# HDSC_HC32F005 register map
Vendor: HDSC Co.Ltd; Series: ARMCM0P; File version: 1.2
CPU: CM0 r0p0, little endian, no MPU, no FPU, 3 interrupt priority bits
Registers are 32-bit, read-write, reset 0x0 unless marked. A register's access mark holds for its fields unless they carry their own. Offsets are from the block's base; [hi:lo] are bit positions; {n}, {i} and the like mark numbered series; 'fields as' and 'values as' point back to an identical list.

## I2C
Base 0x40000400
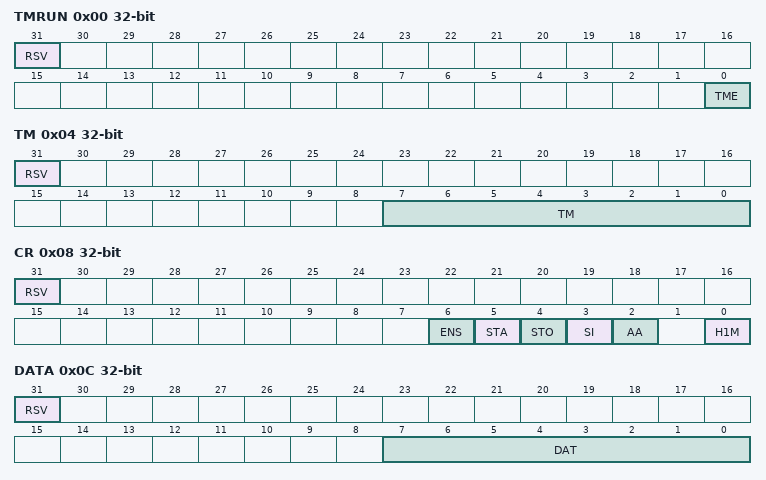
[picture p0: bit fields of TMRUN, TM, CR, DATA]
0x00 TMRUN (reset mask 0x1)
  [31] RSV, [0] TME
0x04 TM (reset mask 0xFF)
  [31] RSV, [7:0] TM
0x08 CR (reset mask 0x7D)
  [31] RSV, [6] ENS, [5] STA, [4] STO, [3] SI, [2] AA, [0] H1M
0x0C DATA (reset mask 0xFF)
  [31] RSV, [7:0] DAT
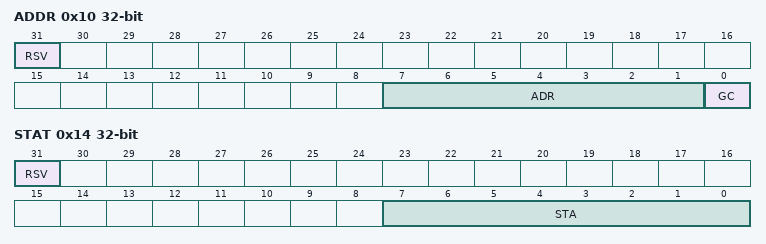
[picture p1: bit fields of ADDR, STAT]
0x10 ADDR (reset mask 0xFF)
  [31] RSV, [7:1] ADR, [0] GC
0x14 STAT ro (reset mask 0xFF)
  [31] RSV rw, [7:0] STA

## LVD
Base 0x40002400; alternate view of ADC
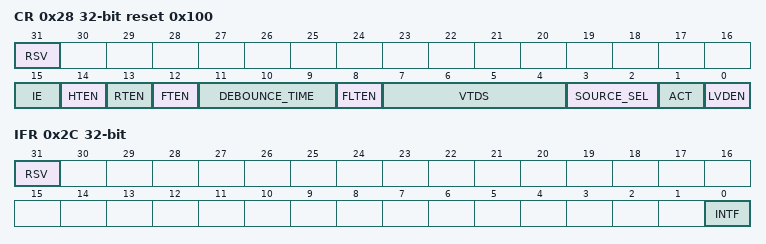
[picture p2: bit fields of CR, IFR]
0x28 CR reset 0x100 (reset mask 0xFFFF)
  [31] RSV, [15] IE, [14] HTEN, [13] RTEN, [12] FTEN, [11:9] DEBOUNCE_TIME, [8] FLTEN, [7:4] VTDS, [3:2] SOURCE_SEL, [1] ACT, [0] LVDEN
0x2C IFR (reset mask 0x1)
  [31] RSV, [0] INTF

## PCA
Base 0x40001000
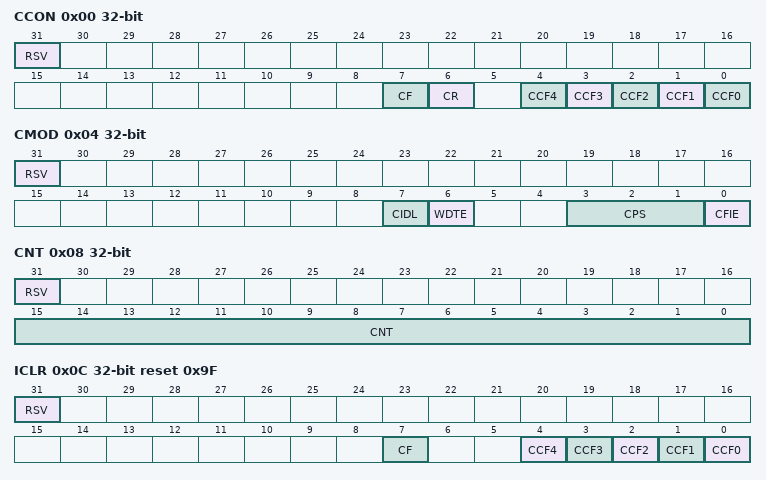
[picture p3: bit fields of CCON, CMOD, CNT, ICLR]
0x00 CCON (reset mask 0xDF)
  [31] RSV, [7] CF, [6] CR, [n] CCF{n} (n=0..4)
0x04 CMOD (reset mask 0xCF)
  [31] RSV, [7] CIDL, [6] WDTE, [3:1] CPS, [0] CFIE
0x08 CNT (reset mask 0xFFFF)
  [31] RSV, [15:0] CNT
0x0C ICLR wo reset 0x9F (reset mask 0x9F)
  [31] RSV rw, [7] CF, [n] CCF{n} (n=0..4)
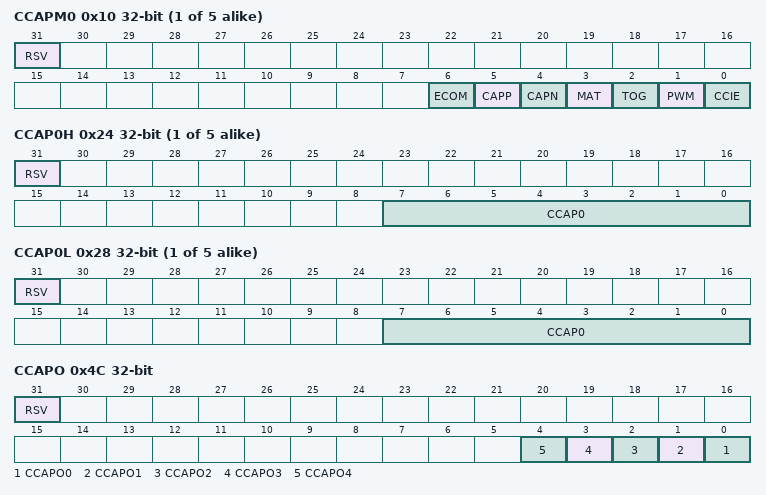
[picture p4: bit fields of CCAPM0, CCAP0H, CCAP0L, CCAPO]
{0x10+4i} CCAPM{i} (reset mask 0x7F) (i=0..4)
  [31] RSV, [6] ECOM, [5] CAPP, [4] CAPN, [3] MAT, [2] TOG, [1] PWM, [0] CCIE
{0x24+8i} CCAP{i}H (reset mask 0xFF) (i=0..4)
  [31] RSV, [7:0] CCAP{i}
{0x28+8i} CCAP{i}L (reset mask 0xFF) (i=0..4)
  [31] RSV, [7:0] CCAP{i}
0x4C CCAPO (reset mask 0x1F)
  [31] RSV, [n] CCAPO{n} (n=0..4)
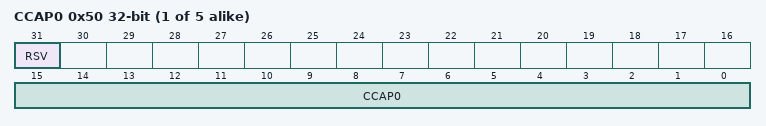
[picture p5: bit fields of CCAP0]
{0x50+4i} CCAP{i} (reset mask 0xFFFF) (i=0..4)
  [31] RSV, [15:0] CCAP{i}

## RAM
Base 0x40020400
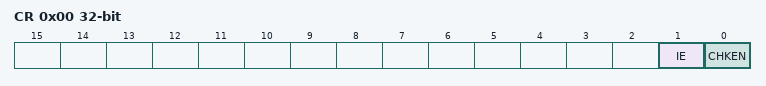
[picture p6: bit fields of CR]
0x00 CR
  [1] IE, [0] CHKEN
0x04 ERRADDR ro
  [11:0] ERRADDR
0x08 IFR ro
  [0] ERR
0x0C ICLR ro
  [0] ERRCLR wo

## RESET
Base 0x4000201C
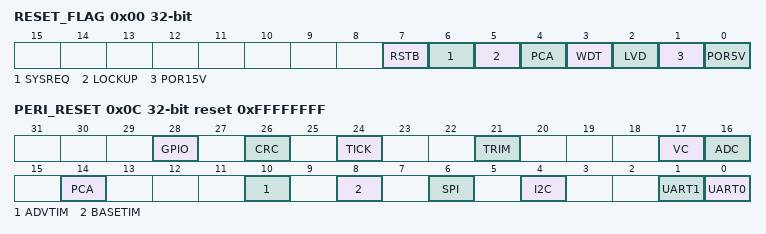
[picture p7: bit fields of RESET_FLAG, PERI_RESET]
0x00 RESET_FLAG
  [7] RSTB, [6] SYSREQ, [5] LOCKUP, [4] PCA, [3] WDT, [2] LVD, [1] POR15V, [0] POR5V
0x0C PERI_RESET reset 0xFFFFFFFF
  [28] GPIO, [26] CRC, [24] TICK, [21] TRIM, [17] VC, [16] ADC, [14] PCA, [10] ADVTIM, [8] BASETIM, [6] SPI, [4] I2C, [1] UART1, [0] UART0

## SPI
Base 0x40000800
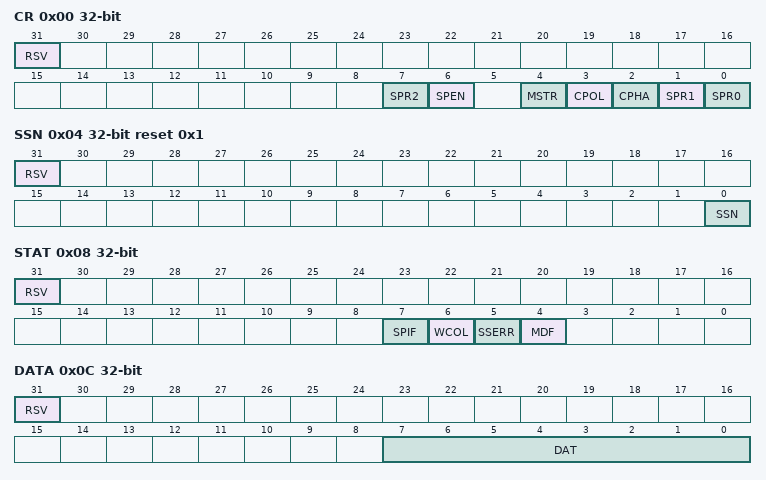
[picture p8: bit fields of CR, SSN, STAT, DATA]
0x00 CR (reset mask 0xDF)
  [31] RSV, [7] SPR2, [6] SPEN, [4] MSTR, [3] CPOL, [2] CPHA, [1] SPR1, [0] SPR0
0x04 SSN reset 0x1 (reset mask 0x1)
  [31] RSV, [0] SSN
0x08 STAT ro (reset mask 0xBE)
  [31] RSV rw, [7] SPIF, [6] WCOL, [5] SSERR, [4] MDF
0x0C DATA (reset mask 0xFF)
  [31] RSV, [7:0] DAT

## SYSCTRL
Base 0x40002000
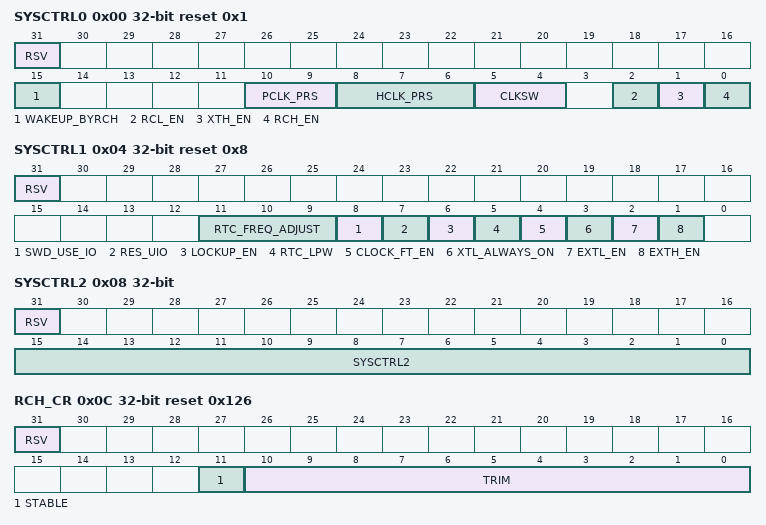
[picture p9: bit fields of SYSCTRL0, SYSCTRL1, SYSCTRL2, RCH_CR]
0x00 SYSCTRL0 reset 0x1 (reset mask 0x9FFF)
  [31] RSV, [15] WAKEUP_BYRCH, [10:9] PCLK_PRS, [8:6] HCLK_PRS, [5:4] CLKSW, [2] RCL_EN, [1] XTH_EN, [0] RCH_EN
0x04 SYSCTRL1 reset 0x8 (reset mask 0xF7E)
  [31] RSV, [11:9] RTC_FREQ_ADJUST, [8] SWD_USE_IO, [7] RES_UIO, [6] LOCKUP_EN, [5] RTC_LPW, [4] CLOCK_FT_EN, [3] XTL_ALWAYS_ON, [2] EXTL_EN, [1] EXTH_EN
0x08 SYSCTRL2 wo (reset mask 0xFFFF)
  [31] RSV rw, [15:0] SYSCTRL2
0x0C RCH_CR reset 0x126 (reset mask 0xFFF)
  [31] RSV, [11] STABLE ro, [10:0] TRIM
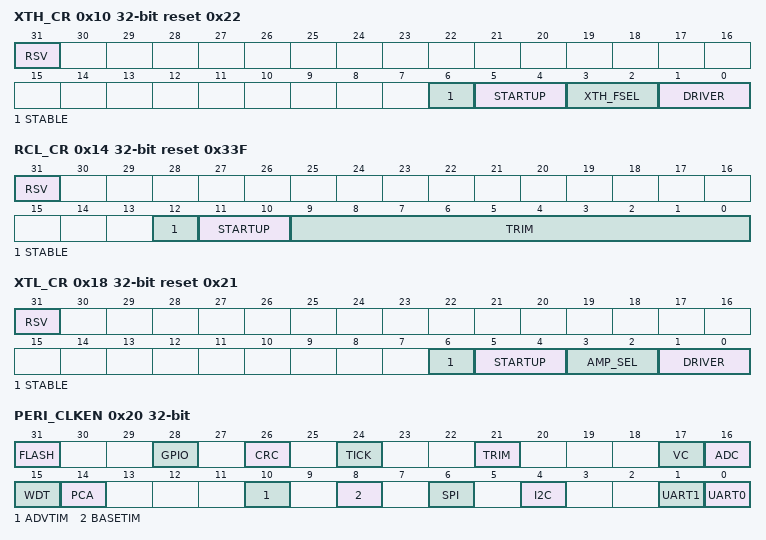
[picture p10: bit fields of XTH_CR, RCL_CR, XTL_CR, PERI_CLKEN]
0x10 XTH_CR reset 0x22 (reset mask 0x7F)
  [31] RSV, [6] STABLE ro, [5:4] STARTUP, [3:2] XTH_FSEL, [1:0] DRIVER
0x14 RCL_CR reset 0x33F (reset mask 0x1FFF)
  [31] RSV, [12] STABLE ro, [11:10] STARTUP, [9:0] TRIM
0x18 XTL_CR reset 0x21 (reset mask 0x7F)
  [31] RSV, [6] STABLE ro, [5:4] STARTUP, [3:2] AMP_SEL, [1:0] DRIVER
0x20 PERI_CLKEN
  [31] FLASH, [28] GPIO, [26] CRC, [24] TICK, [21] TRIM, [17] VC, [16] ADC, [15] WDT, [14] PCA, [10] ADVTIM, [8] BASETIM, [6] SPI, [4] I2C, [1] UART1, [0] UART0
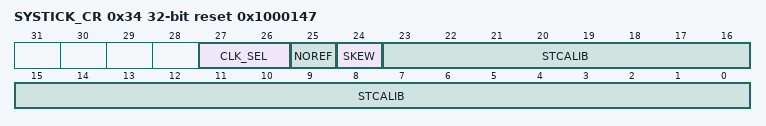
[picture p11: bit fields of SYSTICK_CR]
0x34 SYSTICK_CR reset 0x1000147
  [27:26] CLK_SEL, [25] NOREF, [24] SKEW, [23:0] STCALIB

## TIM0 — desc TIM
Base 0x40000C00
Same registers: TIM1 0x40000C20, TIM2 0x40000C40
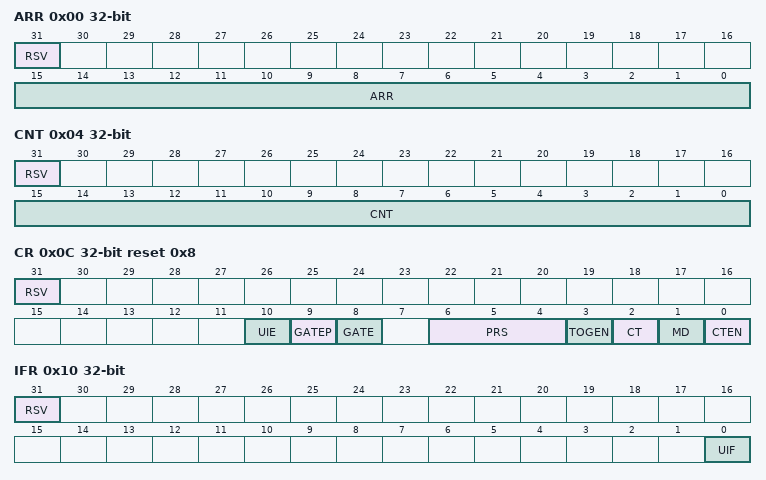
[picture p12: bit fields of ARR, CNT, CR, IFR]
0x00 ARR (reset mask 0xFFFF)
  [31] RSV, [15:0] ARR
0x04 CNT (reset mask 0xFFFF)
  [31] RSV, [15:0] CNT
0x08 CNT32
0x0C CR reset 0x8 (reset mask 0x77F)
  [31] RSV, [10] UIE, [9] GATEP, [8] GATE, [6:4] PRS, [3] TOGEN, [2] CT, [1] MD, [0] CTEN
0x10 IFR ro (reset mask 0x1)
  [31] RSV rw, [0] UIF
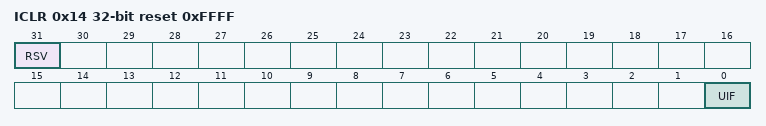
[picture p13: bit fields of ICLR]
0x14 ICLR wo reset 0xFFFF (reset mask 0x1)
  [31] RSV rw, [0] UIF

## UART0 — desc UART
Base 0x40000000
Same registers: UART1 0x40000100
0x00 SBUF
  [7:0] SBUF
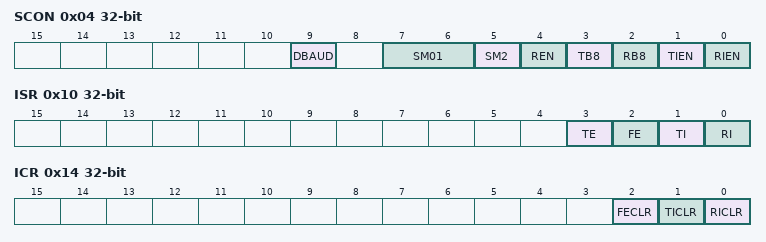
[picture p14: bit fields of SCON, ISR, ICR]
0x04 SCON
  [9] DBAUD, [7:6] SM01, [5] SM2, [4] REN, [3] TB8, [2] RB8, [1] TIEN, [0] RIEN
0x08 SADDR
  [7:0] SADDR
0x0C SADEN
  [7:0] SADEN
0x10 ISR ro
  [3] TE, [2] FE, [1] TI, [0] RI
0x14 ICR wo
  [2] FECLR, [1] TICLR rw, [0] RICLR rw

## VC
Base 0x40002400; alternate view of ADC
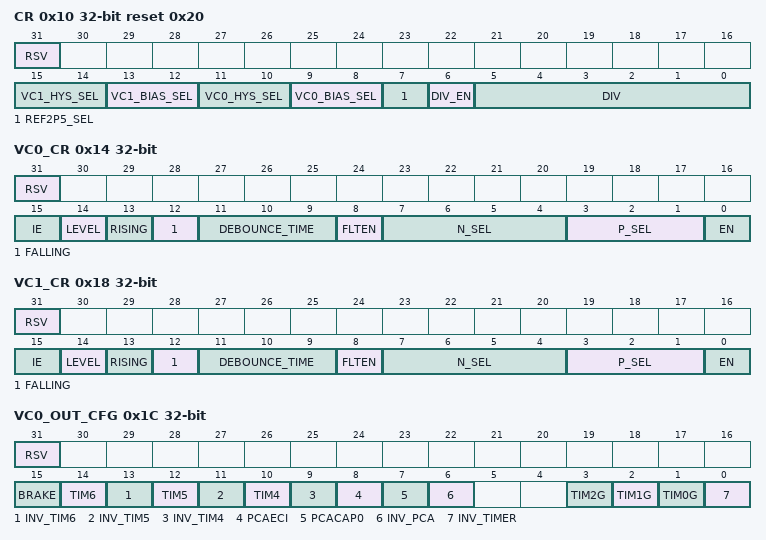
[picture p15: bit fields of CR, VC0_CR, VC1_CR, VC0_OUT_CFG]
0x10 CR reset 0x20 (reset mask 0xFFFF)
  [31] RSV, [15:14] VC1_HYS_SEL, [13:12] VC1_BIAS_SEL, [11:10] VC0_HYS_SEL, [9:8] VC0_BIAS_SEL, [7] REF2P5_SEL, [6] DIV_EN, [5:0] DIV
0x14 VC0_CR (reset mask 0x1FFFF)
  [31] RSV, [15] IE, [14] LEVEL, [13] RISING, [12] FALLING, [11:9] DEBOUNCE_TIME, [8] FLTEN, [7:4] N_SEL, [3:1] P_SEL, [0] EN
0x18 VC1_CR (reset mask 0x1FFFF)
  fields as VC0_CR
0x1C VC0_OUT_CFG (reset mask 0xFE3F)
  [31] RSV, [15] BRAKE, [14] TIM6, [13] INV_TIM6, [12] TIM5, [11] INV_TIM5, [10] TIM4, [9] INV_TIM4, [8] PCAECI, [7] PCACAP0, [6] INV_PCA, [3] TIM2G, [2] TIM1G, [1] TIM0G, [0] INV_TIMER
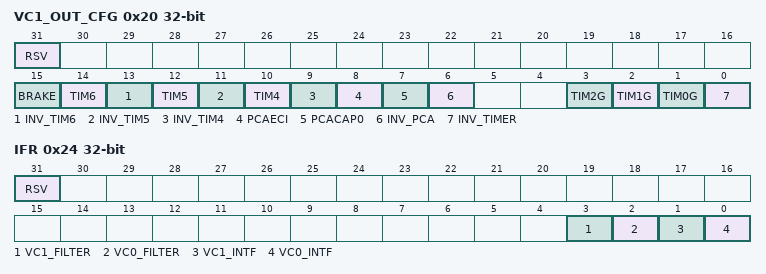
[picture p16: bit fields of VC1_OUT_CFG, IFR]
0x20 VC1_OUT_CFG (reset mask 0xFEFF)
  fields as VC0_OUT_CFG
0x24 IFR (reset mask 0xF)
  [31] RSV, [3] VC1_FILTER ro, [2] VC0_FILTER ro, [1] VC1_INTF, [0] VC0_INTF

## WDT
Base 0x40000C00; alternate view of TIM0
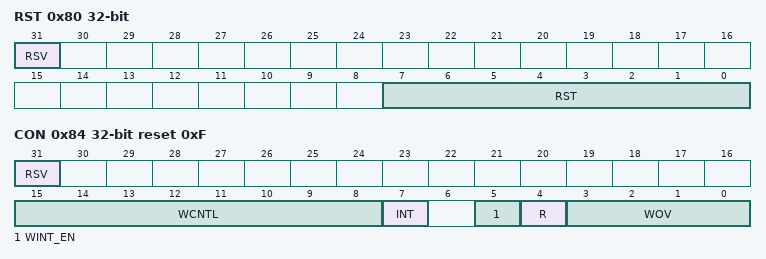
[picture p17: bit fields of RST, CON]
0x80 RST wo (reset mask 0xFF)
  [31] RSV rw, [7:0] RST
0x84 CON reset 0xF (reset mask 0xFFBF)
  [31] RSV, [15:8] WCNTL ro, [7] INT ro, [5] WINT_EN, [4] R ro, [3:0] WOV
